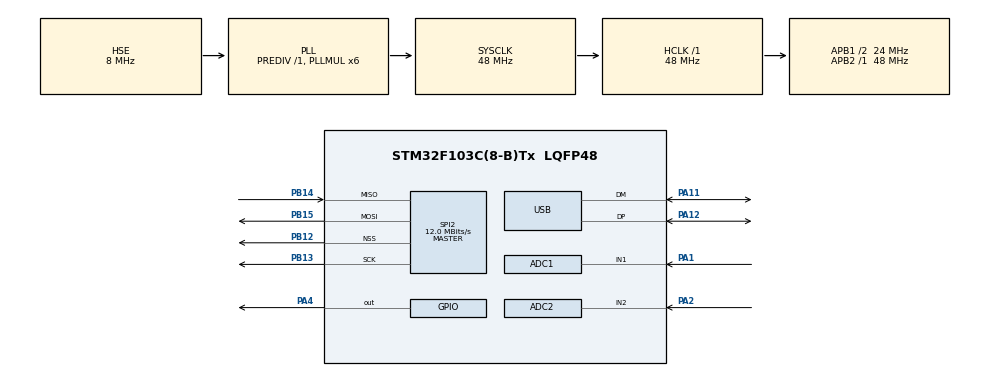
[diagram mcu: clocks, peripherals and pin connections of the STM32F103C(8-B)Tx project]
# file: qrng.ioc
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ADC1.Channel-0\#ChannelRegularConversion=ADC_CHANNEL_1
ADC1.NbrOfConversionFlag=1
ADC1.Rank-0\#ChannelRegularConversion=1
ADC1.SamplingTime-0\#ChannelRegularConversion=ADC_SAMPLETIME_1CYCLE_5
ADC1.master=1
ADC2.Channel-1\#ChannelRegularConversion=ADC_CHANNEL_2
ADC2.NbrOfConversionFlag=1
ADC2.Rank-1\#ChannelRegularConversion=1
ADC2.SamplingTime-1\#ChannelRegularConversion=ADC_SAMPLETIME_1CYCLE_5
FREERTOS.Tasks01=defaultTask,24,128,StartDefaultTask,Default,NULL,Dynamic,NULL,NULL
Mcu.Family=STM32F1
Mcu.Name=STM32F103C(8-B)Tx
Mcu.Package=LQFP48
NVIC.PriorityGroup=NVIC_PRIORITYGROUP_4
NVIC.TIM1_UP_IRQn=true\:0\:0\:false\:false\:true\:false\:false\:true
NVIC.TimeBase=TIM1_UP_IRQn
NVIC.TimeBaseIP=TIM1
NVIC.USB_LP_CAN1_RX0_IRQn=true\:5\:0\:false\:false\:true\:true\:false\:true
PA1.Signal=ADCx_IN1
PA11.Mode=Device
PA11.Signal=USB_DM
PA12.Mode=Device
PA12.Signal=USB_DP
PA13.Mode=Trace_Asynchronous_SW
PA13.Signal=SYS_JTMS-SWDIO
PA14.Mode=Trace_Asynchronous_SW
PA14.Signal=SYS_JTCK-SWCLK
PA2.Signal=ADCx_IN2
PA4.Signal=GPIO_Output
PB12.Mode=NSS_Signal_Hard_Output
PB12.Signal=SPI2_NSS
PB13.Mode=Full_Duplex_Master
PB13.Signal=SPI2_SCK
PB14.Mode=Full_Duplex_Master
PB14.Signal=SPI2_MISO
PB15.Mode=Full_Duplex_Master
PB15.Signal=SPI2_MOSI
PB3.Mode=Trace_Asynchronous_SW
PB3.Signal=SYS_JTDO-TRACESWO
PD0-OSC_IN.Mode=HSE-External-Clock-Source
PD0-OSC_IN.Signal=RCC_OSC_IN
PD1-OSC_OUT.Mode=HSE-External-Clock-Source
PD1-OSC_OUT.Signal=RCC_OSC_OUT
ProjectManager.HeapSize=0x200
ProjectManager.StackSize=0x400
ProjectManager.TargetToolchain=Makefile
RCC.ADCPresc=RCC_ADCPCLK2_DIV4
RCC.AHBFreq_Value=48000000
RCC.APB1CLKDivider=RCC_HCLK_DIV2
RCC.APB1Freq_Value=24000000
RCC.APB1TimFreq_Value=48000000
RCC.APB2Freq_Value=48000000
RCC.APB2TimFreq_Value=48000000
RCC.HCLKFreq_Value=48000000
RCC.PLLMUL=RCC_PLL_MUL6
RCC.PLLSourceVirtual=RCC_PLLSOURCE_HSE
RCC.SYSCLKFreq_VALUE=48000000
RCC.SYSCLKSource=RCC_SYSCLKSOURCE_PLLCLK
RCC.USBFreq_Value=48000000
SH.ADCx_IN1.0=ADC1_IN1,IN1
SH.ADCx_IN2.0=ADC2_IN2,IN2
SPI2.CalculateBaudRate=12.0 MBits/s
SPI2.Direction=SPI_DIRECTION_2LINES
SPI2.Mode=SPI_MODE_MASTER
SPI2.VirtualNSS=VM_NSSHARD
SPI2.VirtualType=VM_MASTER
USB_DEVICE.CLASS_NAME_FS=CUSTOM_HID
USB_DEVICE.CONFIGURATION_STRING_CUSTOMHID_FS=V1
USB_DEVICE.MANUFACTURER_STRING=Spooky Manufacturing
USB_DEVICE.PRODUCT_STRING_CUSTOMHID_FS=QRNG
USB_DEVICE.USBD_DEBUG_LEVEL=3
USB_DEVICE.USBD_SELF_POWERED=0
USB_DEVICE.VirtualMode=CustomHid
USB_DEVICE.VirtualModeFS=Custom_Hid_FS
VP_CRC_VS_CRC.Mode=CRC_Activate
VP_FATFS_VS_Generic.Mode=User_defined
VP_FREERTOS_VS_CMSIS_V2.Mode=CMSIS_V2
VP_IWDG_VS_IWDG.Mode=IWDG_Activate
VP_SYS_VS_tim1.Mode=TIM1
VP_USB_DEVICE_VS_USB_DEVICE_CUSTOM_HID_FS.Mode=CUSTOM_HID_FS
board=custom

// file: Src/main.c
/* USER CODE BEGIN Header */
/**
  ******************************************************************************
  * @file           : main.c
  * @brief          : Main program body
  ******************************************************************************
  * @attention
  *
  * <h2><center>&copy; Copyright (c) 2020 STMicroelectronics.
  * All rights reserved.</center></h2>
  *
  * This software component is licensed by ST under Ultimate Liberty license
  * SLA0044, the "License"; You may not use this file except in compliance with
  * the License. You may obtain a copy of the License at:
  *                             www.st.com/SLA0044
  *
  ******************************************************************************
  */
/* USER CODE END Header */

#include "main.h"
#include "cmsis_os.h"
#include "fatfs.h"
#include "usb_device.h"

ADC_HandleTypeDef hadc1;
ADC_HandleTypeDef hadc2;

CRC_HandleTypeDef hcrc;

IWDG_HandleTypeDef hiwdg;

SPI_HandleTypeDef hspi2;

/* Definitions for defaultTask */
osThreadId_t defaultTaskHandle;
const osThreadAttr_t defaultTask_attributes = {
  .name = "defaultTask",
  .priority = (osPriority_t) osPriorityNormal,
  .stack_size = 128 * 4
};

void SystemClock_Config(void);
static void MX_GPIO_Init(void);
static void MX_ADC1_Init(void);
static void MX_IWDG_Init(void);
static void MX_CRC_Init(void);
static void MX_SPI2_Init(void);
static void MX_ADC2_Init(void);
void StartDefaultTask(void *argument);

int main(void)
{

  /* MCU Configuration--------------------------------------------------------*/

  /* Reset of all peripherals, Initializes the Flash interface and the Systick. */
  HAL_Init();

  /* Configure the system clock */
  SystemClock_Config();

  /* Initialize all configured peripherals */
  MX_GPIO_Init();
  MX_ADC1_Init();
  MX_IWDG_Init();
  MX_CRC_Init();
  MX_SPI2_Init();
  MX_FATFS_Init();
  MX_ADC2_Init();

  /* Init scheduler */
  osKernelInitialize();

  /* Create the thread(s) */
  /* creation of defaultTask */
  defaultTaskHandle = osThreadNew(StartDefaultTask, NULL, &defaultTask_attributes);

  /* Start scheduler */
  osKernelStart();

  /* We should never get here as control is now taken by the scheduler */
  /* Infinite loop */
  while (1)
  {

  }
}

void SystemClock_Config(void)
{
  RCC_OscInitTypeDef RCC_OscInitStruct = {0};
  RCC_ClkInitTypeDef RCC_ClkInitStruct = {0};
  RCC_PeriphCLKInitTypeDef PeriphClkInit = {0};

  /** Initializes the CPU, AHB and APB busses clocks
  */
  RCC_OscInitStruct.OscillatorType = RCC_OSCILLATORTYPE_LSI|RCC_OSCILLATORTYPE_HSE;
  RCC_OscInitStruct.HSEState = RCC_HSE_BYPASS;
  RCC_OscInitStruct.HSEPredivValue = RCC_HSE_PREDIV_DIV1;
  RCC_OscInitStruct.HSIState = RCC_HSI_ON;
  RCC_OscInitStruct.LSIState = RCC_LSI_ON;
  RCC_OscInitStruct.PLL.PLLState = RCC_PLL_ON;
  RCC_OscInitStruct.PLL.PLLSource = RCC_PLLSOURCE_HSE;
  RCC_OscInitStruct.PLL.PLLMUL = RCC_PLL_MUL6;
  if (HAL_RCC_OscConfig(&RCC_OscInitStruct) != HAL_OK)
  {
    Error_Handler();
  }
  /** Initializes the CPU, AHB and APB busses clocks
  */
  RCC_ClkInitStruct.ClockType = RCC_CLOCKTYPE_HCLK|RCC_CLOCKTYPE_SYSCLK
                              |RCC_CLOCKTYPE_PCLK1|RCC_CLOCKTYPE_PCLK2;
  RCC_ClkInitStruct.SYSCLKSource = RCC_SYSCLKSOURCE_PLLCLK;
  RCC_ClkInitStruct.AHBCLKDivider = RCC_SYSCLK_DIV1;
  RCC_ClkInitStruct.APB1CLKDivider = RCC_HCLK_DIV2;
  RCC_ClkInitStruct.APB2CLKDivider = RCC_HCLK_DIV1;

  if (HAL_RCC_ClockConfig(&RCC_ClkInitStruct, FLASH_LATENCY_1) != HAL_OK)
  {
    Error_Handler();
  }
  PeriphClkInit.PeriphClockSelection = RCC_PERIPHCLK_ADC|RCC_PERIPHCLK_USB;
  PeriphClkInit.AdcClockSelection = RCC_ADCPCLK2_DIV4;
  PeriphClkInit.UsbClockSelection = RCC_USBCLKSOURCE_PLL;
  if (HAL_RCCEx_PeriphCLKConfig(&PeriphClkInit) != HAL_OK)
  {
    Error_Handler();
  }
}

static void MX_ADC1_Init(void)
{

  ADC_ChannelConfTypeDef sConfig = {0};

  /** Common config
  */
  hadc1.Instance = ADC1;
  hadc1.Init.ScanConvMode = ADC_SCAN_DISABLE;
  hadc1.Init.ContinuousConvMode = DISABLE;
  hadc1.Init.DiscontinuousConvMode = DISABLE;
  hadc1.Init.ExternalTrigConv = ADC_SOFTWARE_START;
  hadc1.Init.DataAlign = ADC_DATAALIGN_RIGHT;
  hadc1.Init.NbrOfConversion = 1;
  if (HAL_ADC_Init(&hadc1) != HAL_OK)
  {
    Error_Handler();
  }
  /** Configure Regular Channel
  */
  sConfig.Channel = ADC_CHANNEL_1;
  sConfig.Rank = ADC_REGULAR_RANK_1;
  sConfig.SamplingTime = ADC_SAMPLETIME_1CYCLE_5;
  if (HAL_ADC_ConfigChannel(&hadc1, &sConfig) != HAL_OK)
  {
    Error_Handler();
  }

}

static void MX_ADC2_Init(void)
{

  ADC_ChannelConfTypeDef sConfig = {0};

  /** Common config
  */
  hadc2.Instance = ADC2;
  hadc2.Init.ScanConvMode = ADC_SCAN_DISABLE;
  hadc2.Init.ContinuousConvMode = DISABLE;
  hadc2.Init.DiscontinuousConvMode = DISABLE;
  hadc2.Init.ExternalTrigConv = ADC_SOFTWARE_START;
  hadc2.Init.DataAlign = ADC_DATAALIGN_RIGHT;
  hadc2.Init.NbrOfConversion = 1;
  if (HAL_ADC_Init(&hadc2) != HAL_OK)
  {
    Error_Handler();
  }
  /** Configure Regular Channel
  */
  sConfig.Channel = ADC_CHANNEL_2;
  sConfig.Rank = ADC_REGULAR_RANK_1;
  sConfig.SamplingTime = ADC_SAMPLETIME_1CYCLE_5;
  if (HAL_ADC_ConfigChannel(&hadc2, &sConfig) != HAL_OK)
  {
    Error_Handler();
  }

}

static void MX_CRC_Init(void)
{

  hcrc.Instance = CRC;
  if (HAL_CRC_Init(&hcrc) != HAL_OK)
  {
    Error_Handler();
  }

}

static void MX_IWDG_Init(void)
{

  hiwdg.Instance = IWDG;
  hiwdg.Init.Prescaler = IWDG_PRESCALER_4;
  hiwdg.Init.Reload = 4095;
  if (HAL_IWDG_Init(&hiwdg) != HAL_OK)
  {
    Error_Handler();
  }

}

static void MX_SPI2_Init(void)
{

  /* SPI2 parameter configuration*/
  hspi2.Instance = SPI2;
  hspi2.Init.Mode = SPI_MODE_MASTER;
  hspi2.Init.Direction = SPI_DIRECTION_2LINES;
  hspi2.Init.DataSize = SPI_DATASIZE_8BIT;
  hspi2.Init.CLKPolarity = SPI_POLARITY_LOW;
  hspi2.Init.CLKPhase = SPI_PHASE_1EDGE;
  hspi2.Init.NSS = SPI_NSS_HARD_OUTPUT;
  hspi2.Init.BaudRatePrescaler = SPI_BAUDRATEPRESCALER_2;
  hspi2.Init.FirstBit = SPI_FIRSTBIT_MSB;
  hspi2.Init.TIMode = SPI_TIMODE_DISABLE;
  hspi2.Init.CRCCalculation = SPI_CRCCALCULATION_DISABLE;
  hspi2.Init.CRCPolynomial = 10;
  if (HAL_SPI_Init(&hspi2) != HAL_OK)
  {
    Error_Handler();
  }

}

static void MX_GPIO_Init(void)
{
  GPIO_InitTypeDef GPIO_InitStruct = {0};

  /* GPIO Ports Clock Enable */
  __HAL_RCC_GPIOC_CLK_ENABLE();
  __HAL_RCC_GPIOD_CLK_ENABLE();
  __HAL_RCC_GPIOA_CLK_ENABLE();
  __HAL_RCC_GPIOB_CLK_ENABLE();

  /*Configure GPIO pin Output Level */
  HAL_GPIO_WritePin(GPIOA, GPIO_PIN_4, GPIO_PIN_RESET);

  /*Configure GPIO pins : PC13 PC14 PC15 */
  GPIO_InitStruct.Pin = GPIO_PIN_13|GPIO_PIN_14|GPIO_PIN_15;
  GPIO_InitStruct.Mode = GPIO_MODE_ANALOG;
  HAL_GPIO_Init(GPIOC, &GPIO_InitStruct);

  /*Configure GPIO pins : PA0 PA3 PA5 PA6
                           PA7 PA8 PA9 PA10
                           PA15 */
  GPIO_InitStruct.Pin = GPIO_PIN_0|GPIO_PIN_3|GPIO_PIN_5|GPIO_PIN_6
                          |GPIO_PIN_7|GPIO_PIN_8|GPIO_PIN_9|GPIO_PIN_10
                          |GPIO_PIN_15;
  GPIO_InitStruct.Mode = GPIO_MODE_ANALOG;
  HAL_GPIO_Init(GPIOA, &GPIO_InitStruct);

  /*Configure GPIO pin : PA4 */
  GPIO_InitStruct.Pin = GPIO_PIN_4;
  GPIO_InitStruct.Mode = GPIO_MODE_OUTPUT_PP;
  GPIO_InitStruct.Pull = GPIO_NOPULL;
  GPIO_InitStruct.Speed = GPIO_SPEED_FREQ_LOW;
  HAL_GPIO_Init(GPIOA, &GPIO_InitStruct);

  /*Configure GPIO pins : PB0 PB1 PB2 PB10
                           PB11 PB4 PB5 PB6
                           PB7 PB8 PB9 */
  GPIO_InitStruct.Pin = GPIO_PIN_0|GPIO_PIN_1|GPIO_PIN_2|GPIO_PIN_10
                          |GPIO_PIN_11|GPIO_PIN_4|GPIO_PIN_5|GPIO_PIN_6
                          |GPIO_PIN_7|GPIO_PIN_8|GPIO_PIN_9;
  GPIO_InitStruct.Mode = GPIO_MODE_ANALOG;
  HAL_GPIO_Init(GPIOB, &GPIO_InitStruct);

}

void StartDefaultTask(void *argument)
{
  /* init code for USB_DEVICE */
  MX_USB_DEVICE_Init();
  /* USER CODE BEGIN 5 */
  /* Infinite loop */
  for(;;)
  {
    HAL_GPIO_TogglePin(GPIOA, GPIO_PIN_4);
    osDelay(30);
    HAL_GPIO_TogglePin(GPIOA, GPIO_PIN_4);
 }
  /* USER CODE END 5 */
}

 /**
  * @brief  Period elapsed callback in non blocking mode
  * @note   This function is called  when TIM1 interrupt took place, inside
  * HAL_TIM_IRQHandler(). It makes a direct call to HAL_IncTick() to increment
  * a global variable "uwTick" used as application time base.
  * @param  htim : TIM handle
  * @retval None
  */
void HAL_TIM_PeriodElapsedCallback(TIM_HandleTypeDef *htim)
{
  if (htim->Instance == TIM1) {
    HAL_IncTick();
  }
}

void Error_Handler(void)
{
}

/************************ (C) COPYRIGHT STMicroelectronics *****END OF FILE****/
